# HC32F467 register map
File version: 1.0
CPU: CM4 r0p1, little endian, MPU, FPU, 4 interrupt priority bits
Registers are 32-bit, read-write, reset 0x0 unless marked. A register's access mark holds for its fields unless they carry their own. Offsets are from the block's base; [hi:lo] are bit positions; {n}, {i} and the like mark numbered series.

## AES
Base 0x40008000
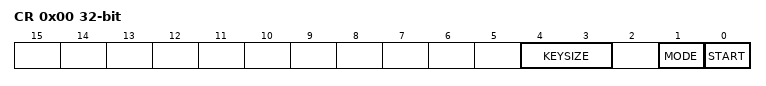
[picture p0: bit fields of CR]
0x00 CR
  [4:3] KEYSIZE, [1] MODE, [0] START
{0x10+4i} DR{i} (i=0..3)
{0x20+4i} KR{i} (i=0..7)

## AOS
Base 0x40010800
0x00 INTSFTTRG wo
  [0] STRG
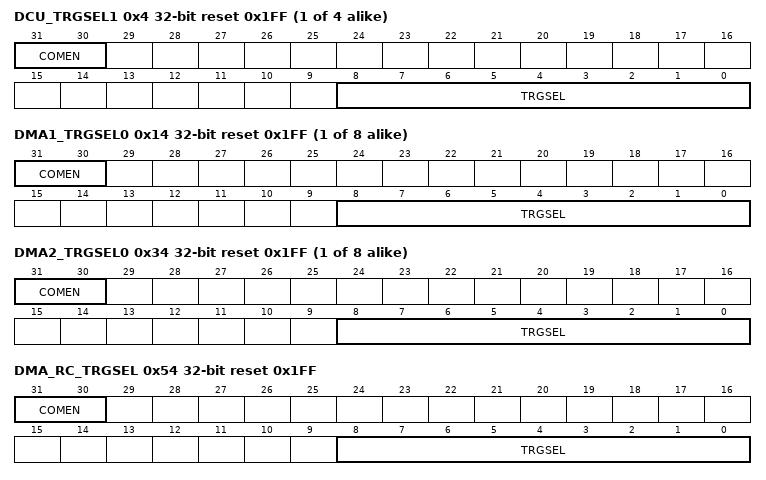
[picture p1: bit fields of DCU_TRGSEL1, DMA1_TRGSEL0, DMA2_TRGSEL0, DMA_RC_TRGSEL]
{0x0+4i} DCU_TRGSEL{i} reset 0x1FF (i=1..4)
  [31:30] COMEN, [8:0] TRGSEL
{0x14+4i} DMA1_TRGSEL{i} reset 0x1FF (i=0..7)
  [31:30] COMEN, [8:0] TRGSEL
{0x34+4i} DMA2_TRGSEL{i} reset 0x1FF (i=0..7)
  [31:30] COMEN, [8:0] TRGSEL
0x54 DMA_RC_TRGSEL reset 0x1FF
  [31:30] COMEN, [8:0] TRGSEL
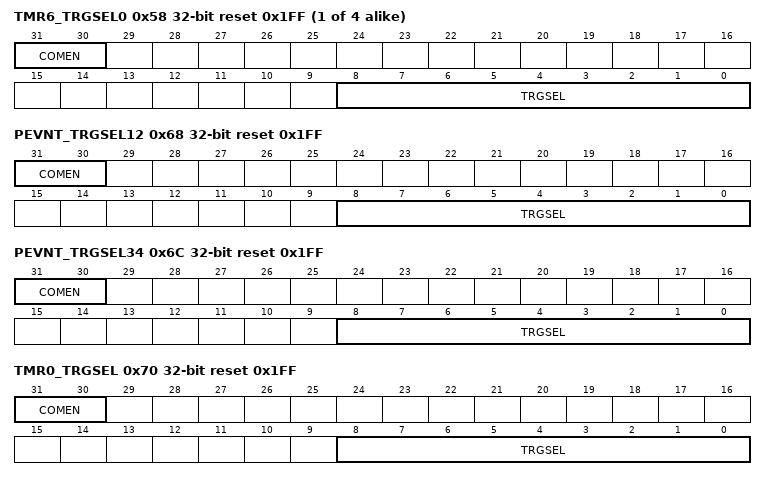
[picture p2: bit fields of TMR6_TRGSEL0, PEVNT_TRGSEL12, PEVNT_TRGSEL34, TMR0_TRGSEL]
{0x58+4i} TMR6_TRGSEL{i} reset 0x1FF (i=0..3)
  [31:30] COMEN, [8:0] TRGSEL
0x68 PEVNT_TRGSEL12 reset 0x1FF
  [31:30] COMEN, [8:0] TRGSEL
0x6C PEVNT_TRGSEL34 reset 0x1FF
  [31:30] COMEN, [8:0] TRGSEL
0x70 TMR0_TRGSEL reset 0x1FF
  [31:30] COMEN, [8:0] TRGSEL
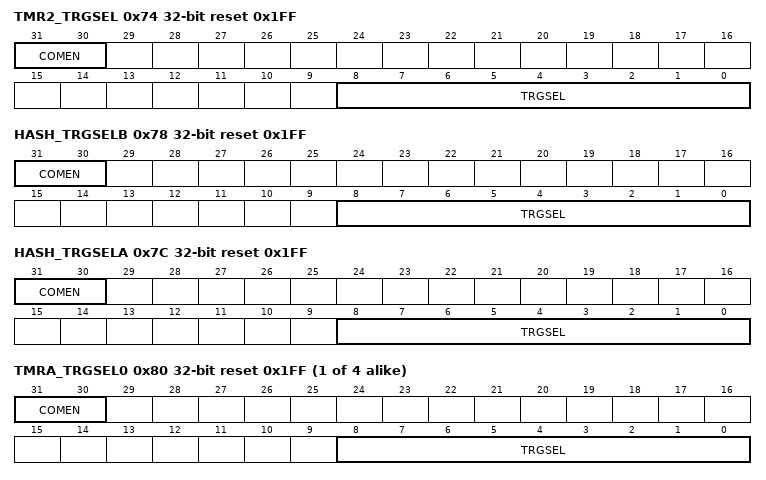
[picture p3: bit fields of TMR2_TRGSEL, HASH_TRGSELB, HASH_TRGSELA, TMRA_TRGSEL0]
0x74 TMR2_TRGSEL reset 0x1FF
  [31:30] COMEN, [8:0] TRGSEL
0x78 HASH_TRGSELB reset 0x1FF
  [31:30] COMEN, [8:0] TRGSEL
0x7C HASH_TRGSELA reset 0x1FF
  [31:30] COMEN, [8:0] TRGSEL
{0x80+4i} TMRA_TRGSEL{i} reset 0x1FF (i=0..3)
  [31:30] COMEN, [8:0] TRGSEL
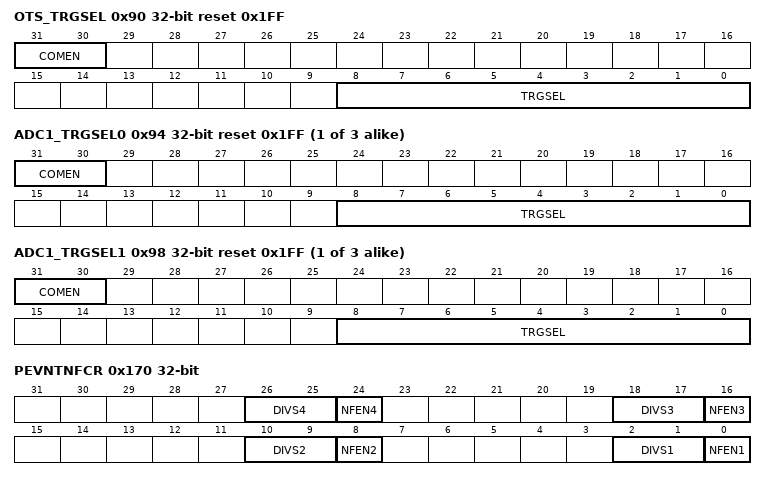
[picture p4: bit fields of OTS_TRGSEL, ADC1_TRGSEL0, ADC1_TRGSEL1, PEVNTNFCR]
0x90 OTS_TRGSEL reset 0x1FF
  [31:30] COMEN, [8:0] TRGSEL
{0x8C+8i} ADC{i}_TRGSEL0 reset 0x1FF (i=1..3)
  [31:30] COMEN, [8:0] TRGSEL
{0x90+8i} ADC{i}_TRGSEL1 reset 0x1FF (i=1..3)
  [31:30] COMEN, [8:0] TRGSEL
0xAC COMTRG1 reset 0x1FF
  [8:0] COMTRG
0xB0 COMTRG2 reset 0x1FF
  [8:0] COMTRG
{0xE4+0x1C*i} PEVNTDIRR{i} (i=1..4)
  [15:0] PDIR
{0xE8+0x1C*i} PEVNTIDR{i} ro (i=1..4)
  [15:0] PIN
{0xEC+0x1C*i} PEVNTODR{i} (i=1..4)
  [15:0] POUT
{0xF0+0x1C*i} PEVNTORR{i} (i=1..4)
  [15:0] POR
{0xF4+0x1C*i} PEVNTOSR{i} (i=1..4)
  [15:0] POS
{0xF8+0x1C*i} PEVNTRISR{i} (i=1..4)
  [15:0] RIS
{0xFC+0x1C*i} PEVNTFALR{i} (i=1..4)
  [15:0] FAL
0x170 PEVNTNFCR
  [8n-6:8n-7] DIVS{n} (n=1..4), [8n-8] NFEN{n} (n=1..4)

## CAN1 — desc CAN
Base 0x40009000
Same registers: CAN2 0x40078000
0x00 RBUF ro
0x50 TBUF
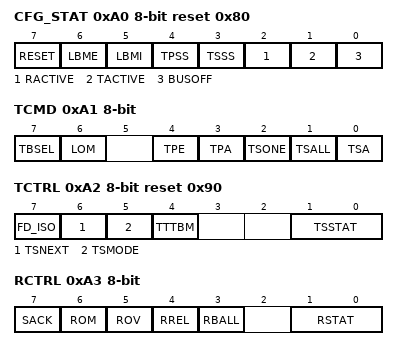
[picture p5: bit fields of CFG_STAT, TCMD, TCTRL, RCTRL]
0xA0 CFG_STAT 8-bit reset 0x80
  [7] RESET, [6] LBME, [5] LBMI, [4] TPSS, [3] TSSS, [2] RACTIVE ro, [1] TACTIVE ro, [0] BUSOFF
0xA1 TCMD 8-bit
  [7] TBSEL, [6] LOM, [4] TPE, [3] TPA, [2] TSONE, [1] TSALL, [0] TSA
0xA2 TCTRL 8-bit reset 0x90
  [7] FD_ISO, [6] TSNEXT, [5] TSMODE, [4] TTTBM, [1:0] TSSTAT ro
0xA3 RCTRL 8-bit
  [7] SACK, [6] ROM, [5] ROV ro, [4] RREL, [3] RBALL, [1:0] RSTAT ro
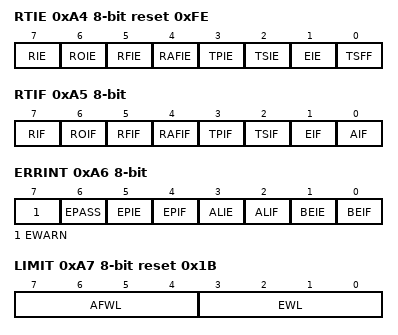
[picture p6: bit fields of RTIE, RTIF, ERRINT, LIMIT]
0xA4 RTIE 8-bit reset 0xFE
  [7] RIE, [6] ROIE, [5] RFIE, [4] RAFIE, [3] TPIE, [2] TSIE, [1] EIE, [0] TSFF ro
0xA5 RTIF 8-bit
  [7] RIF, [6] ROIF, [5] RFIF, [4] RAFIF, [3] TPIF, [2] TSIF, [1] EIF, [0] AIF
0xA6 ERRINT 8-bit
  [7] EWARN ro, [6] EPASS ro, [5] EPIE, [4] EPIF, [3] ALIE, [2] ALIF, [1] BEIE, [0] BEIF
0xA7 LIMIT 8-bit reset 0x1B
  [7:4] AFWL, [3:0] EWL
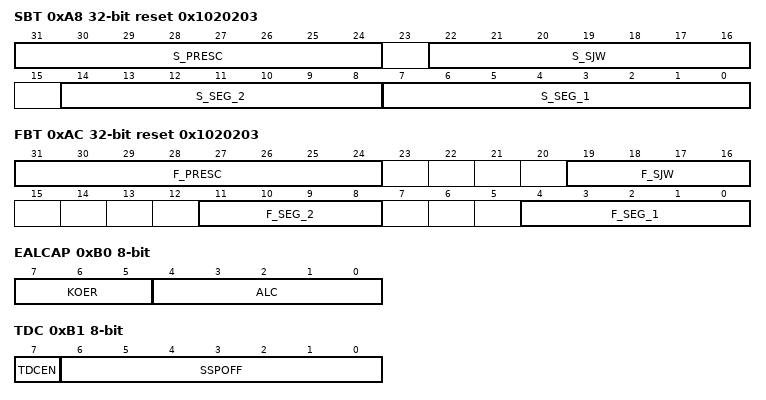
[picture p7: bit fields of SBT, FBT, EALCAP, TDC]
0xA8 SBT reset 0x1020203
  [31:24] S_PRESC, [22:16] S_SJW, [14:8] S_SEG_2, [7:0] S_SEG_1
0xAC FBT reset 0x1020203
  [31:24] F_PRESC, [19:16] F_SJW, [11:8] F_SEG_2, [4:0] F_SEG_1
0xB0 EALCAP 8-bit ro
  [7:5] KOER, [4:0] ALC
0xB1 TDC 8-bit
  [7] TDCEN, [6:0] SSPOFF
0xB2 RECNT 8-bit
0xB3 TECNT 8-bit
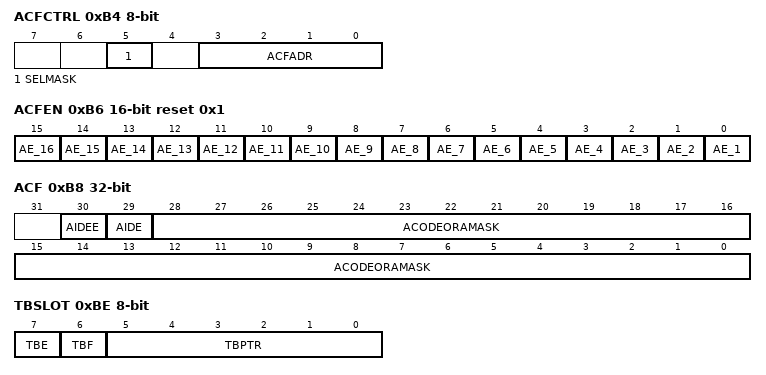
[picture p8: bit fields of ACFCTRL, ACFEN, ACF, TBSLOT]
0xB4 ACFCTRL 8-bit
  [5] SELMASK, [3:0] ACFADR
0xB6 ACFEN 16-bit reset 0x1
  [n-1] AE_{n} (n=1..16)
0xB8 ACF
  [30] AIDEE, [29] AIDE, [28:0] ACODEORAMASK
0xBE TBSLOT 8-bit
  [7] TBE, [6] TBF, [5:0] TBPTR
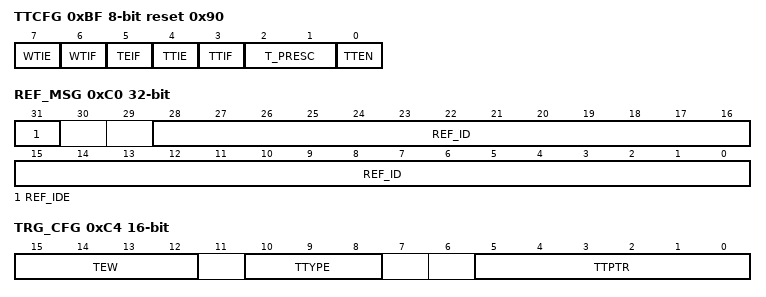
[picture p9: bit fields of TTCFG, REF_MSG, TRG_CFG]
0xBF TTCFG 8-bit reset 0x90
  [7] WTIE, [6] WTIF, [5] TEIF, [4] TTIE, [3] TTIF, [2:1] T_PRESC, [0] TTEN
0xC0 REF_MSG
  [31] REF_IDE, [28:0] REF_ID
0xC4 TRG_CFG 16-bit
  [15:12] TEW, [10:8] TTYPE, [5:0] TTPTR
0xC6 TT_TRIG 16-bit
0xC8 TT_WTRIG 16-bit reset 0xFFFF

## CMP1 — desc CMP
Base 0x4004A000
Same registers: CMP3 0x4004A400
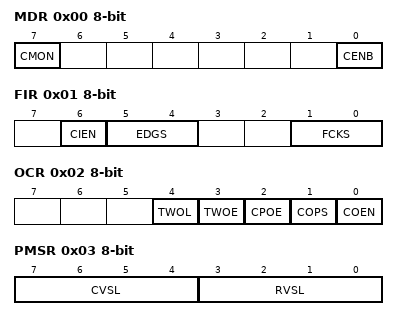
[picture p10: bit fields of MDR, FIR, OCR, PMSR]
0x00 MDR 8-bit
  [7] CMON ro, [0] CENB
0x01 FIR 8-bit
  [6] CIEN, [5:4] EDGS, [1:0] FCKS
0x02 OCR 8-bit
  [4] TWOL, [3] TWOE, [2] CPOE, [1] COPS, [0] COEN
0x03 PMSR 8-bit
  [7:4] CVSL, [3:0] RVSL
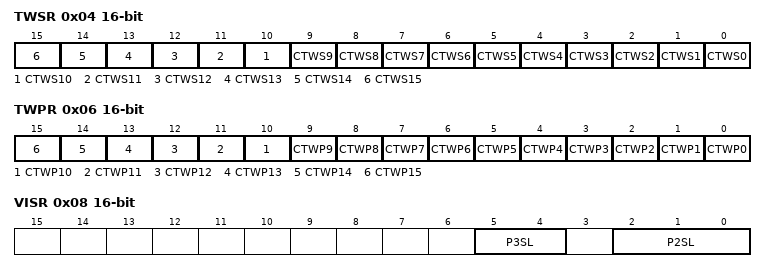
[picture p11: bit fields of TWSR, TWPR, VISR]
0x04 TWSR 16-bit
  [n] CTWS{n} (n=0..15)
0x06 TWPR 16-bit
  [n] CTWP{n} (n=0..15)
0x08 VISR 16-bit
  [5:4] P3SL, [2:0] P2SL

## CMP2 — desc CMP
Base 0x4004A010
Registers as CMP1; these are added or differ:
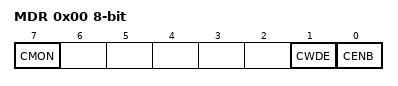
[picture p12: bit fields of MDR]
0x00 MDR 8-bit
  [7] CMON ro, [1] CWDE, [0] CENB
